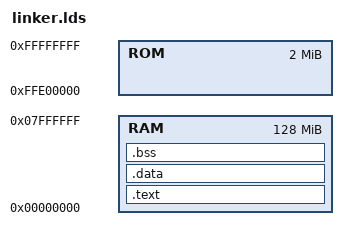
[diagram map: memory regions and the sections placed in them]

ENTRY(_start)

MEMORY
{
        RAM : ORIGIN = 0x00000000, LENGTH = 128M
        ROM : ORIGIN = 0xFFE00000, LENGTH = 2M
}

SECTIONS
{
        /**********************************************************************
         *                                                                    *
         **********************************************************************/
        .text :
        {
                _text_start = .;
                *(.startup)
                *(.vectortable)
                *(.text)
                *(.text.*)
                *(.rodata)
                *(.rodata.*)
                *(.got1)
                . = ALIGN(0x10);
                _text_end = .;
        } > RAM
        /**********************************************************************
         *                                                                    *
         **********************************************************************/
        .data :
        {
                _data_start = .;
                *(.data)
                *(.data.*)
                /* _sdata = .; */
                *(.sdata)
                *(.sdata.*)
                /* _sdata2 = .; */
                *(.sdata2)
                *(.got.plt)
                *(.got)
                . = ALIGN(0x10);
                _data_end = .;
        } > RAM
        /**********************************************************************
         *                                                                    *
         **********************************************************************/
        .bss ADDR(.data) + SIZEOF(.data) (NOLOAD) :
        {
                _bss_start = .;
                *(.bss)
                *(.bss.*)
                *(COMMON)
                *(.sbss)
                *(.sbss.*)
                *(.scommon)
                *(.dynbss)
                . = ALIGN(0x10);
                _bss_end = .;
        } > RAM
        /**********************************************************************
         *                                                                    *
         **********************************************************************/
        /DISCARD/ :
        {
                *(.comment)
        }
}

